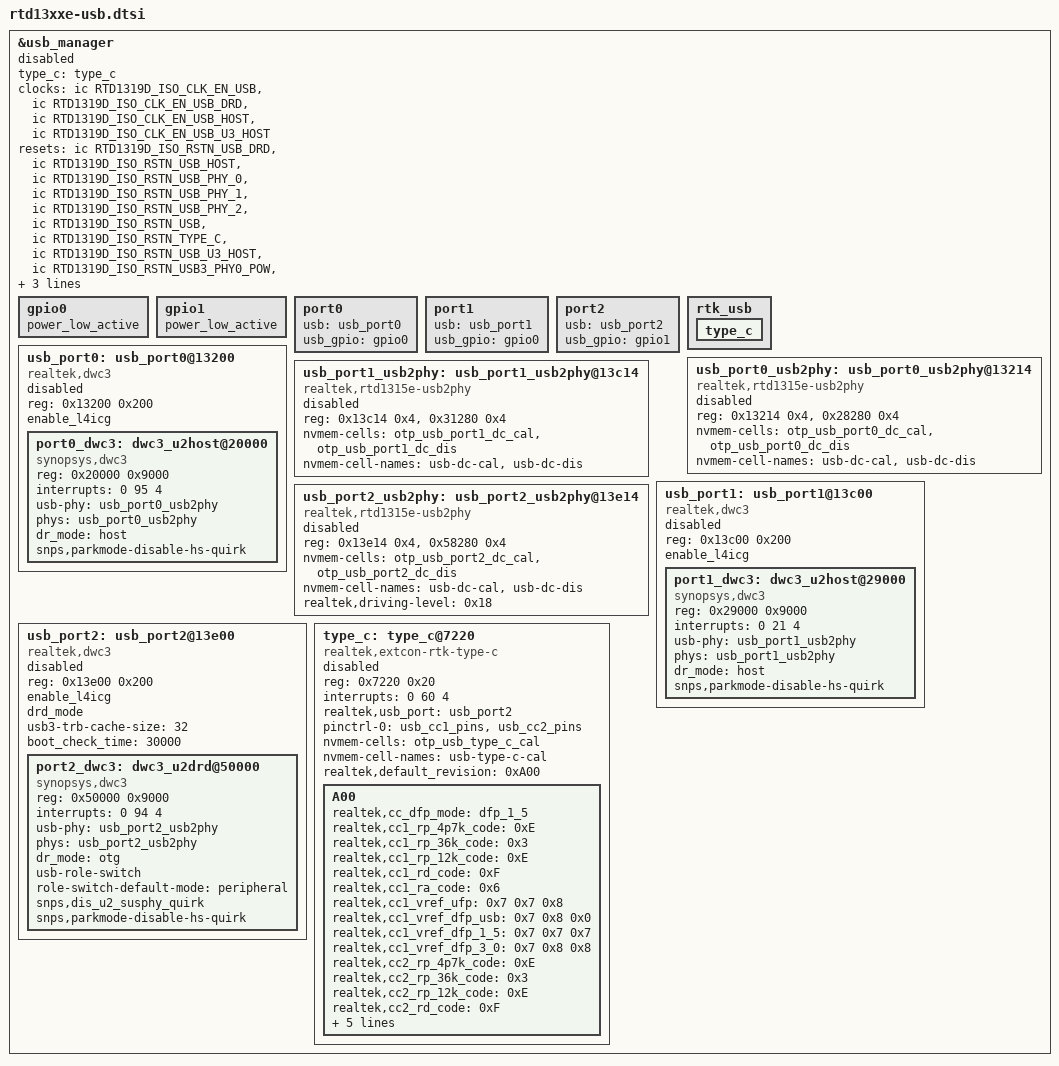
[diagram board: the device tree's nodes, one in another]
// SPDX-License-Identifier: (GPL-2.0-or-later OR BSD-2-Clause)
/*
 * Realtek RTD1315e SoC USB
 *
 * Copyright (c) 2022 Realtek Semiconductor Corp.
 */

&usb_manager {
	//usb_iso_mode;  /* ISO mode is only port suspend (Default disable) */
	//en_usb_storage_reprobe; /* To enable usb storage re-probe*/
	//rescue_usb; /* For rescue dtb use */

	status = "disabled";

	/* set type c node */
	type_c = <&type_c>;

	gpio0: gpio0 {
		//realtek,power-gpio = <&gpio 48 GPIO_ACTIVE_HIGH>;
		power_low_active;
	};

	gpio1: gpio1 {
		//realtek,power-gpio = <&gpio 49 GPIO_ACTIVE_HIGH>;
		power_low_active;
	};

	port0 {
		usb = <&usb_port0>;
		usb_gpio = <&gpio0>;
	};

	port1 {
		usb = <&usb_port1>;
		usb_gpio = <&gpio0>;
	};

	port2 {
		usb = <&usb_port2>;
		usb_gpio = <&gpio1>;
	};

	rtk_usb {
		type_c {
			/* For connector switch */
			//realtek,connector_switch-gpio = <&gpio 49 GPIO_ACTIVE_HIGH>;
			/* For plug side switch */
			//realtek,plug_side_switch-gpio = <&gpio 53 GPIO_ACTIVE_HIGH>;
		};
	};
};

&usb_manager {
	clocks = <&ic RTD1319D_ISO_CLK_EN_USB>, /* clk_en_usb */
			<&ic RTD1319D_ISO_CLK_EN_USB_DRD>,  /* clk_en_usb_drd (port0 phy to u2drd clock) */
			<&ic RTD1319D_ISO_CLK_EN_USB_HOST>,  /* clk_en_usb_host0 (port1 phy to u2host clock) */
			<&ic RTD1319D_ISO_CLK_EN_USB_U3_HOST>;  /* clk_en_usb_host1 (port2 phy to u3drd clock) */
	clock-names = "clk_en_usb", /*clk_en_usb*/
			"clk_en_phy0_to_host", /* clk_en_usb_drd (port0 phy to u2drd clock) */
			"clk_en_phy1_to_host", /* clk_en_usb_u2host (port1 phy to u2host clock) */
			"clk_en_phy2_to_host"; /* clk_en_usb_u3host (port2 phy to u3drd clock) */

	resets = <&ic RTD1319D_ISO_RSTN_USB_DRD>, /* rstn_usb_u2drd (port0) */
			<&ic RTD1319D_ISO_RSTN_USB_HOST>, /* rstn_usb_u2host(port1) */
			<&ic RTD1319D_ISO_RSTN_USB_PHY_0>, /* rstn_usb_phy0 (port0 u2phy) */
			<&ic RTD1319D_ISO_RSTN_USB_PHY_1>, /* rstn_usb_phy1 (port1 u2phy) */
			<&ic RTD1319D_ISO_RSTN_USB_PHY_2>, /* rstn_usb_phy2 (port2 u2phy) */
			<&ic RTD1319D_ISO_RSTN_USB>, /* rstn_usb */
			<&ic RTD1319D_ISO_RSTN_TYPE_C>, /* rstn_type_c */
			<&ic RTD1319D_ISO_RSTN_USB_U3_HOST>, /* rstn_usb_u3drd (port2) */
			<&ic RTD1319D_ISO_RSTN_USB3_PHY0_POW>, /* rstn_usb3_phy0 (port0 u3phy) no used */
			<&ic RTD1319D_ISO_RSTN_USB3_P0_MDIO>, /* rstn_usb3_phy0_mdio (port0 u3phy) no used */
			<&ic RTD1319D_ISO_RSTN_USB3_PHY1_POW>, /* rstn_usb3_phy1 (port2 u3phy) */
			<&ic RTD1319D_ISO_RSTN_USB3_P1_MDIO>; /* rstn_usb3_phy1_mdio (port2 u3phy) */

	reset-names = "usb_host0", /* rstn_usb_u2drd (port0) */
			"usb_host1", /* rstn_usb_u2host (port1) */
			"u2phy0", /* rstn_usb_phy0 (port0 u2phy) */
			"u2phy1", /* rstn_usb_phy1 (port1 u2phy) */
			"u2phy2", /* rstn_usb_phy2 (port2 u2phy) */
			"usb", /* rstn_usb */
			"type_c", /* rstn_type_c */
			"usb_host2", /* rstn_usb_u3drd (port2) */
			"u3phy0", /* rstn_usb3_phy0 (port0 u3phy) no used*/
			"u3mdio0", /* rstn_usb3_phy0_mdio (port0 u3phy) no used */
			"u3phy2", /* rstn_usb3_phy1 (port2 u3phy) */
			"u3mdio2"; /* rstn_usb3_phy1_mdio (port2 u3phy) */
};

&usb_manager {
	usb_port0_usb2phy: usb_port0_usb2phy@13214 {
		compatible = "realtek,rtd1315e-usb2phy";
		reg = <0x13214 0x4>, <0x28280 0x4>;
		#phy-cells = <0>;
		nvmem-cells = <&otp_usb_port0_dc_cal>, <&otp_usb_port0_dc_dis>;
		nvmem-cell-names = "usb-dc-cal", "usb-dc-dis";
		status = "disabled";
	};

	usb_port0: usb_port0@13200 {
		compatible = "realtek,dwc3", "syscon", "realtek,rtd-dwc3";
		reg = <0x13200 0x200>;
		#address-cells = <1>;
		#size-cells = <1>;
		ranges;
	};

	usb_port1_usb2phy: usb_port1_usb2phy@13c14 {
		compatible = "realtek,rtd1315e-usb2phy";
		reg = <0x13c14 0x4>, <0x31280 0x4>;
		#phy-cells = <0>;
		nvmem-cells = <&otp_usb_port1_dc_cal>, <&otp_usb_port1_dc_dis>;
		nvmem-cell-names = "usb-dc-cal", "usb-dc-dis";
		status = "disabled";
	};

	usb_port1: usb_port1@13c00 {
		compatible = "realtek,dwc3", "syscon", "realtek,rtd-dwc3";
		reg = <0x13c00 0x200>;
		#address-cells = <1>;
		#size-cells = <1>;
		ranges;
	};

	usb_port2_usb2phy: usb_port2_usb2phy@13e14 {
		compatible = "realtek,rtd1315e-usb2phy";
		reg = <0x13e14 0x4>, <0x58280 0x4>;
		#phy-cells = <0>;
		nvmem-cells = <&otp_usb_port2_dc_cal>, <&otp_usb_port2_dc_dis>;
		nvmem-cell-names = "usb-dc-cal", "usb-dc-dis";
		status = "disabled";

		realtek,driving-level = <0x18>;
	};

	usb_port2: usb_port2@13e00 {
		compatible = "realtek,dwc3", "syscon", "realtek,rtd-dwc3";
		reg = <0x13e00 0x200>;
		#address-cells = <1>;
		#size-cells = <1>;
		ranges;
	};

	type_c: type_c@7220 {
		compatible = "realtek,extcon-rtk-type-c";
		reg = <0x7220 0x20>;
		#address-cells = <1>;
		#size-cells = <1>;
		ranges;
	};
};

&usb_port0 {
	enable_l4icg;
	status = "disabled";

	port0_dwc3: dwc3_u2host@20000 {
		compatible = "synopsys,dwc3", "syscon";
		reg = <0x20000 0x9000>;
		interrupts = <0 95 4>;
		usb-phy = <&usb_port0_usb2phy>;
		phys = <&usb_port0_usb2phy>;
		phy-names = "usb2-phy";
		dr_mode = "host";
		snps,parkmode-disable-hs-quirk; // disable usb2.0 park mode

		status = "okay";
	};
};

&usb_port1 {
	enable_l4icg;
	status = "disabled";

	port1_dwc3: dwc3_u2host@29000 {
		compatible = "synopsys,dwc3", "syscon";
		reg = <0x29000 0x9000>;
		interrupts = <0 21 4>;
		usb-phy = <&usb_port1_usb2phy>;
		phys = <&usb_port1_usb2phy>;
		phy-names = "usb2-phy";
		dr_mode = "host";
		snps,parkmode-disable-hs-quirk; // disable usb2.0 park mode

		status = "okay";
	};
};

&usb_port2 {
	enable_l4icg;
	drd_mode;
	usb3-trb-cache-size = <32>; /* for xhci controller */
	boot_check_time = <30000>; /* ms (At boot Device switch Host time) */
	status = "disabled";

	port2_dwc3: dwc3_u2drd@50000 {
		compatible = "synopsys,dwc3", "syscon";
		reg = <0x50000 0x9000>;
		interrupts = <0 94 4>;
		usb-phy = <&usb_port2_usb2phy>;
		phys = <&usb_port2_usb2phy>;
		phy-names = "usb2-phy";
		dr_mode = "otg"; /* otg, host, peripheral*/
		usb-role-switch;
		role-switch-default-mode = "peripheral"; /* host, peripheral*/
		snps,dis_u2_susphy_quirk; // Disable u2phy suspend for drd
		snps,parkmode-disable-hs-quirk; // disable usb2.0 park mode

		status = "okay";
	};
};

&type_c {
	interrupts = <0 60 4>;
	//debug; /*to enable debug log*/

	realtek,usb_port = <&usb_port2>; /* default usb_port is u2drd*/

	pinctrl-names = "default";
	pinctrl-0 = <&usb_cc1_pins>, <&usb_cc2_pins>;

	nvmem-cells = <&otp_usb_type_c_cal>;
	nvmem-cell-names = "usb-type-c-cal";

	status = "disabled";

	realtek,default_revision = <0xA00>;
	A00 {
		realtek,cc_dfp_mode = "dfp_1_5"; /*dfp_3_0, dfp_1_5, dfp_usb*/
		realtek,cc1_rp_4p7k_code = <0xE>;
		realtek,cc1_rp_36k_code = <0x3>;
		realtek,cc1_rp_12k_code = <0xE>;
		realtek,cc1_rd_code = <0xF>;
		realtek,cc1_ra_code = <0x6>;
		realtek,cc1_vref_ufp = /bits/ 8
			<0x7 0x7 0x8>; /*<1p23v,0p66v,0p2v>*/
		realtek,cc1_vref_dfp_usb = /bits/ 8
			<0x7 0x8 0x0>; /*<0_1p6v,0p2v,unused>*/
		realtek,cc1_vref_dfp_1_5 = /bits/ 8
			<0x7 0x7 0x7>; /*<1_1p6v,0p4v,0p2v>*/
		realtek,cc1_vref_dfp_3_0 = /bits/ 8
			<0x7 0x8 0x8>; /*<2p6v,0p8v,0p2v>*/
		realtek,cc2_rp_4p7k_code = <0xE>;
		realtek,cc2_rp_36k_code = <0x3>;
		realtek,cc2_rp_12k_code = <0xE>;
		realtek,cc2_rd_code = <0xF>;
		realtek,cc2_ra_code = <0x6>;
		realtek,cc2_vref_ufp = /bits/ 8
			<0x7 0x7 0x8>; /*<1p23v,0p66v,0p2v>*/
		realtek,cc2_vref_dfp_usb = /bits/ 8
			<0x7 0x8 0x0>; /*<0_1p6v,0p2v,unused>*/
		realtek,cc2_vref_dfp_1_5 = /bits/ 8
			<0x7 0x7 0x8>; /*<1_1p6v,0p4v,0p2v>*/
		realtek,cc2_vref_dfp_3_0 = /bits/ 8
			<0x7 0x8 0x8>; /*<2p6v,0p8v,0p2v>*/
	};
};
